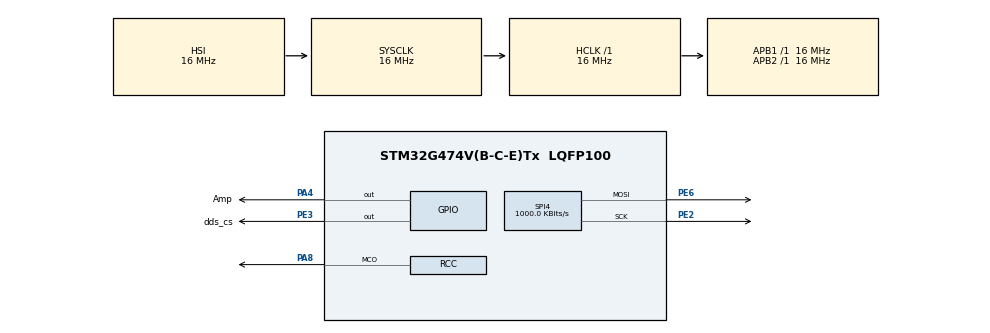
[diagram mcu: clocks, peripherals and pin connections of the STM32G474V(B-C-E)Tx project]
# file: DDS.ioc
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Mcu.Family=STM32G4
Mcu.Name=STM32G474V(B-C-E)Tx
Mcu.Package=LQFP100
NVIC.PriorityGroup=NVIC_PRIORITYGROUP_4
PA4.GPIO_Label=Amp
PA4.PinState=GPIO_PIN_SET
PA4.Signal=GPIO_Output
PA8.GPIO_Speed=GPIO_SPEED_FREQ_MEDIUM
PA8.Mode=Clock-out
PA8.Signal=RCC_MCO
PE2.GPIO_PuPd=GPIO_PULLUP
PE2.Mode=TX_Only_Simplex_Unidirect_Master
PE2.Signal=SPI4_SCK
PE3.GPIO_Label=dds_cs
PE3.PinState=GPIO_PIN_SET
PE3.Signal=GPIO_Output
PE6.Mode=TX_Only_Simplex_Unidirect_Master
PE6.Signal=SPI4_MOSI
PF0-OSC_IN.Mode=HSE-External-Oscillator
PF0-OSC_IN.Signal=RCC_OSC_IN
PF1-OSC_OUT.Mode=HSE-External-Oscillator
PF1-OSC_OUT.Signal=RCC_OSC_OUT
ProjectManager.HeapSize=0x200
ProjectManager.StackSize=0x400
ProjectManager.TargetToolchain=STM32CubeIDE
RCC.AHBFreq_Value=16000000
RCC.APB1Freq_Value=16000000
RCC.APB1TimFreq_Value=16000000
RCC.APB2Freq_Value=16000000
RCC.APB2TimFreq_Value=16000000
RCC.CortexFreq_Value=16000000
RCC.EXTERNAL_CLOCK_VALUE=12288000
RCC.HCLKFreq_Value=16000000
RCC.HSE_VALUE=25000000
RCC.HSI48_VALUE=48000000
RCC.HSI_VALUE=16000000
RCC.LSE_VALUE=32768
RCC.RCC_MCO1Source=RCC_MCO1SOURCE_HSE
RCC.SYSCLKFreq_VALUE=16000000
RCC.USBFreq_Value=64000000
RCC.VCOOutputFreq_Value=128000000
SPI4.BaudRatePrescaler=SPI_BAUDRATEPRESCALER_16
SPI4.CLKPolarity=SPI_POLARITY_HIGH
SPI4.CalculateBaudRate=1000.0 KBits/s
SPI4.DataSize=SPI_DATASIZE_16BIT
SPI4.Direction=SPI_DIRECTION_2LINES
SPI4.Mode=SPI_MODE_MASTER
SPI4.VirtualType=VM_MASTER
VP_SYS_VS_DBSignals.Mode=DisableDeadBatterySignals
board=custom

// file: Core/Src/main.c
/* USER CODE BEGIN Header */
/**
  ******************************************************************************
  * @file           : main.c
  * @brief          : Main program body
  ******************************************************************************
  * @attention
  *
  * Copyright (c) 2025 STMicroelectronics.
  * All rights reserved.
  *
  * This software is licensed under terms that can be found in the LICENSE file
  * in the root directory of this software component.
  * If no LICENSE file comes with this software, it is provided AS-IS.
  *
  ******************************************************************************
  */
/* USER CODE END Header */
#include "main.h"

SPI_HandleTypeDef hspi4;

void SystemClock_Config(void);
static void MX_GPIO_Init(void);
static void MX_SPI4_Init(void);

/* USER CODE BEGIN 0 */
void ad9834_send(uint16_t cmd)
{
  HAL_GPIO_WritePin(dds_cs_GPIO_Port, dds_cs_Pin, GPIO_PIN_RESET);

  HAL_SPI_Transmit(&hspi4, (uint8_t*)&cmd, 1, 10);

  HAL_GPIO_WritePin(dds_cs_GPIO_Port, dds_cs_Pin, GPIO_PIN_SET);
}
/* USER CODE END 0 */

int main(void)
{

  /* MCU Configuration--------------------------------------------------------*/

  /* Reset of all peripherals, Initializes the Flash interface and the Systick. */
  HAL_Init();

  /* Configure the system clock */
  SystemClock_Config();

  /* Initialize all configured peripherals */
  MX_GPIO_Init();
  MX_SPI4_Init();
  /* USER CODE BEGIN 2 */
  ad9834_send(0x2100);
  ad9834_send(0x50C7);
  ad9834_send(0x4000);
  ad9834_send(0xC000);
  ad9834_send(0x2000);
  /* USER CODE END 2 */

  /* Infinite loop */
  while (1)
  {

  }
}

void SystemClock_Config(void)
{
  RCC_OscInitTypeDef RCC_OscInitStruct = {0};
  RCC_ClkInitTypeDef RCC_ClkInitStruct = {0};

  /** Configure the main internal regulator output voltage
  */
  HAL_PWREx_ControlVoltageScaling(PWR_REGULATOR_VOLTAGE_SCALE1);

  /** Initializes the RCC Oscillators according to the specified parameters
  * in the RCC_OscInitTypeDef structure.
  */
  RCC_OscInitStruct.OscillatorType = RCC_OSCILLATORTYPE_HSI|RCC_OSCILLATORTYPE_HSE;
  RCC_OscInitStruct.HSEState = RCC_HSE_ON;
  RCC_OscInitStruct.HSIState = RCC_HSI_ON;
  RCC_OscInitStruct.HSICalibrationValue = RCC_HSICALIBRATION_DEFAULT;
  RCC_OscInitStruct.PLL.PLLState = RCC_PLL_NONE;
  if (HAL_RCC_OscConfig(&RCC_OscInitStruct) != HAL_OK)
  {
    Error_Handler();
  }

  /** Initializes the CPU, AHB and APB buses clocks
  */
  RCC_ClkInitStruct.ClockType = RCC_CLOCKTYPE_HCLK|RCC_CLOCKTYPE_SYSCLK
                              |RCC_CLOCKTYPE_PCLK1|RCC_CLOCKTYPE_PCLK2;
  RCC_ClkInitStruct.SYSCLKSource = RCC_SYSCLKSOURCE_HSI;
  RCC_ClkInitStruct.AHBCLKDivider = RCC_SYSCLK_DIV1;
  RCC_ClkInitStruct.APB1CLKDivider = RCC_HCLK_DIV1;
  RCC_ClkInitStruct.APB2CLKDivider = RCC_HCLK_DIV1;

  if (HAL_RCC_ClockConfig(&RCC_ClkInitStruct, FLASH_LATENCY_0) != HAL_OK)
  {
    Error_Handler();
  }
  HAL_RCC_MCOConfig(RCC_MCO1, RCC_MCO1SOURCE_HSE, RCC_MCODIV_1);
}

static void MX_SPI4_Init(void)
{

  /* SPI4 parameter configuration*/
  hspi4.Instance = SPI4;
  hspi4.Init.Mode = SPI_MODE_MASTER;
  hspi4.Init.Direction = SPI_DIRECTION_2LINES;
  hspi4.Init.DataSize = SPI_DATASIZE_16BIT;
  hspi4.Init.CLKPolarity = SPI_POLARITY_HIGH;
  hspi4.Init.CLKPhase = SPI_PHASE_1EDGE;
  hspi4.Init.NSS = SPI_NSS_SOFT;
  hspi4.Init.BaudRatePrescaler = SPI_BAUDRATEPRESCALER_16;
  hspi4.Init.FirstBit = SPI_FIRSTBIT_MSB;
  hspi4.Init.TIMode = SPI_TIMODE_DISABLE;
  hspi4.Init.CRCCalculation = SPI_CRCCALCULATION_DISABLE;
  hspi4.Init.CRCPolynomial = 7;
  hspi4.Init.CRCLength = SPI_CRC_LENGTH_DATASIZE;
  hspi4.Init.NSSPMode = SPI_NSS_PULSE_ENABLE;
  if (HAL_SPI_Init(&hspi4) != HAL_OK)
  {
    Error_Handler();
  }

}

static void MX_GPIO_Init(void)
{
  GPIO_InitTypeDef GPIO_InitStruct = {0};

  /* GPIO Ports Clock Enable */
  __HAL_RCC_GPIOE_CLK_ENABLE();
  __HAL_RCC_GPIOF_CLK_ENABLE();
  __HAL_RCC_GPIOA_CLK_ENABLE();

  /*Configure GPIO pin Output Level */
  HAL_GPIO_WritePin(dds_cs_GPIO_Port, dds_cs_Pin, GPIO_PIN_SET);

  /*Configure GPIO pin Output Level */
  HAL_GPIO_WritePin(Amp_GPIO_Port, Amp_Pin, GPIO_PIN_SET);

  /*Configure GPIO pin : dds_cs_Pin */
  GPIO_InitStruct.Pin = dds_cs_Pin;
  GPIO_InitStruct.Mode = GPIO_MODE_OUTPUT_PP;
  GPIO_InitStruct.Pull = GPIO_NOPULL;
  GPIO_InitStruct.Speed = GPIO_SPEED_FREQ_LOW;
  HAL_GPIO_Init(dds_cs_GPIO_Port, &GPIO_InitStruct);

  /*Configure GPIO pin : Amp_Pin */
  GPIO_InitStruct.Pin = Amp_Pin;
  GPIO_InitStruct.Mode = GPIO_MODE_OUTPUT_PP;
  GPIO_InitStruct.Pull = GPIO_NOPULL;
  GPIO_InitStruct.Speed = GPIO_SPEED_FREQ_LOW;
  HAL_GPIO_Init(Amp_GPIO_Port, &GPIO_InitStruct);

  /*Configure GPIO pin : PA8 */
  GPIO_InitStruct.Pin = GPIO_PIN_8;
  GPIO_InitStruct.Mode = GPIO_MODE_AF_PP;
  GPIO_InitStruct.Pull = GPIO_NOPULL;
  GPIO_InitStruct.Speed = GPIO_SPEED_FREQ_MEDIUM;
  GPIO_InitStruct.Alternate = GPIO_AF0_MCO;
  HAL_GPIO_Init(GPIOA, &GPIO_InitStruct);

}

void Error_Handler(void)
{
  __disable_irq();
  while (1)
  {
  }
}
